# max32570 register map
Vendor: Maxim-Integrated; Series: ARMCM4; File version: 1.0
CPU: CM4 r2p1, little endian, MPU, FPU, 3 interrupt priority bits
Registers are 32-bit, read-write, reset 0x0 unless marked. A register's access mark holds for its fields unless they carry their own. Offsets are from the block's base; [hi:lo] are bit positions; {n}, {i} and the like mark numbered series; 'fields as' and 'values as' point back to an identical list.

## TRIMSIR — Trim System Initilazation Registers
Base 0x40005400
0x00 rsv0 — RFU
0x08 BB_SIR2 ro — System Init. Configuration Register 2.
0x0C BB_SIR3 ro — System Init. Configuration Register 3.

## MCR — Misc Control.
Base 0x40006C00
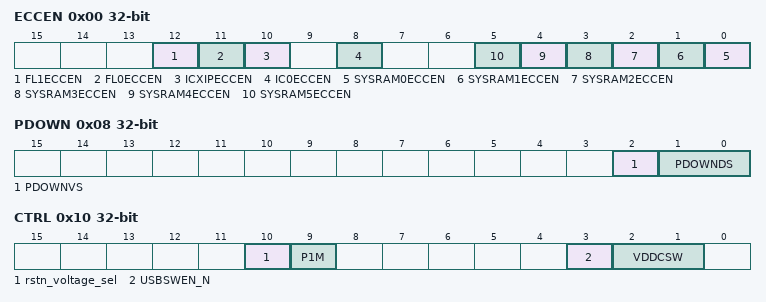
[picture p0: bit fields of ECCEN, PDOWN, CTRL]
0x00 ECCEN — ECC Enable Register
  [all] fields
    0=dis (disabled.); 1=en (enabled.)
  [12] FL1ECCEN — Flash1 ECC Enable.
  [11] FL0ECCEN — Flash0 ECC Enable.
  [10] ICXIPECCEN — IcacheXIP ECC Enable.
  [8] IC0ECCEN — Icache0 ECC Enable.
  [n] SYSRAM{n}ECCEN (n=0..5) — ECC System RAM Enable.
0x08 PDOWN — PDOWN Drive Strength
  [2] PDOWNVS — PDOWN Voltage Select
  [1:0] PDOWNDS — PDOWN Drive Strength
0x10 CTRL — Misc Power State Control Register
  [10] rstn_voltage_sel — Error! Description not Found!
  [9] P1M — Enable the Reset Pad Pull Up Resistors
    0=1m (1MOhm Pullup); 1=25k (25kOhm Pullup.)
  [3] USBSWEN_N — USB Switch Control
    1=off (USB SW off in LP modes); 0=on (USB SW On)
  [2:1] VDDCSW — Controls switching of VCORE

## CAMERAIF — Parallel Camera Interface.
Base 0x4000E000
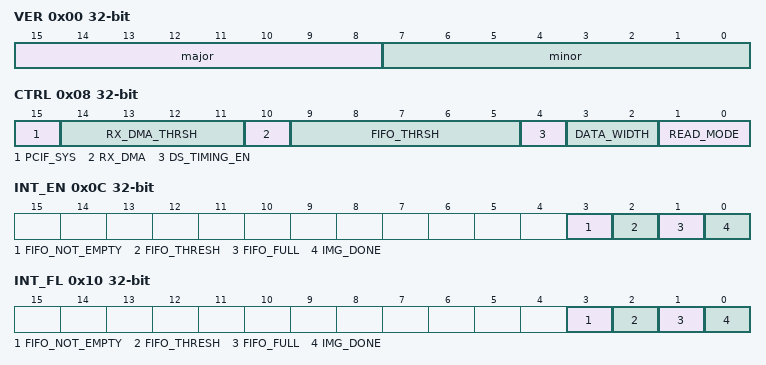
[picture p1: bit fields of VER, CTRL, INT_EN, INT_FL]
0x00 VER — Hardware Version.
  [15:8] major — Major Version Number.
  [7:0] minor — Minor Version Number.
0x04 FIFO_SIZE — FIFO Depth.
  [7:0] fifo_size
0x08 CTRL — Control Register.
  [15] PCIF_SYS — PCIF Control.
    0=dis (PCIF disabled.); 1=en (PCIF enabled.)
  [14:11] RX_DMA_THRSH — DMA Threshold.
  [10] RX_DMA — DMA Enable.
    0=dis (DMA disabled.); 1=en (DMA enabled.)
  [9:5] FIFO_THRSH — Data FIFO Threshold.
  [4] DS_TIMING_EN — DS Timing Enable.
    0=dis (Timing from VSYNC and HSYNC.); 1=en (Timing embedded in data using SAV and EAV codes.)
  [3:2] DATA_WIDTH
    0=8bit; 1=10bit; 2=12bit
  [1:0] READ_MODE
    0=dis (Camera Interface Disabled.); 1=single_img (Single Image Capture.); 2=Continuous Image Capture
0x0C INT_EN — Interrupt Enable Register.
  [3] FIFO_NOT_EMPTY
  [2] FIFO_THRESH — FIFO Threshold Level Met.
  [1] FIFO_FULL
  [0] IMG_DONE — Image Done.
0x10 INT_FL — Interrupt Flag Register.
  fields as INT_EN
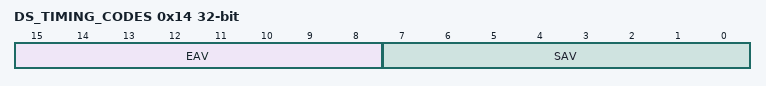
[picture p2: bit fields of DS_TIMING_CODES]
0x14 DS_TIMING_CODES — DS Timing Code Register.
  [15:8] EAV — End Active Video Code.
  [7:0] SAV — Start Active Video Code.
0x30 FIFO_DATA
  [31:0] DATA — Data from FIFO to be read by DMA.

## SRCC — SPIX Cache Controller Registers.
Base 0x40033000
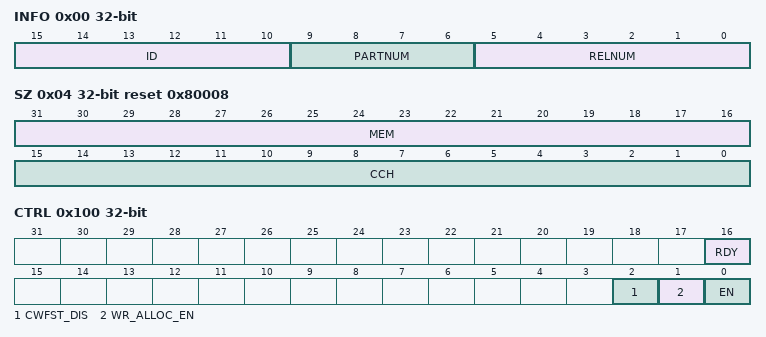
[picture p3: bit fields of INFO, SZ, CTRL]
0x00 INFO ro — Cache ID Register.
  [15:10] ID — Cache ID. This field reflects the value of the C_ID_CACHEID configuration parameter.
  [9:6] PARTNUM — Part Number. This field reflects the value of C_ID_PART_NUMBER configuration parameter.
  [5:0] RELNUM — Release Number. Identifies the RTL release version.
0x04 SZ ro reset 0x80008 — Memory Configuration Register.
  [31:16] MEM — Main Memory Size. Indicates the total size, in units of 128 Kbytes, of code memory accessible to the cache controller.
  [15:0] CCH — Cache Size. Indicates total size in Kbytes of cache.
0x100 CTRL — Cache Control and Status Register.
  [16] RDY — Cache Ready flag. Cleared by hardware when at any time the cache as a whole is invalidated (including a system reset). When this bit is 0, the cache is effectively in bypass mode (instruction fetches will come from main memory or from the line fill buffer). Set by hardware when the invalidate operation is complete and the cache is ready.
    0=notReady; 1=ready
  [2] CWFST_DIS — Critical word first and streaming disable. This bit only writeable while the cache is disabled.
    1=dis (Critical word first and streaming disabled.); 0=en (Critical word first and streaming enabled.)
  [1] WR_ALLOC_EN — Write Allocate Enable. This bit only writable while the cache is disabled.
    0=dis (Write-no-allocate.); 1=en (Write-allocate enabled.)
  [0] EN — Cache Enable. Controls whether the cache is bypassed or is in use. Changing the state of this bit will cause the instruction cache to be flushed and its contents invalidated.
    0=dis (Cache Bypassed. Instruction data is stored in the line fill buffer but is not written to main cache memory array.); 1=en (Cache Enabled.)
0x700 INVALIDATE — Invalidate All Cache Contents. Any time this register location is written (regardless of the data value), the cache controller immediately begins invalidating the entire contents of the cache memory. The cache will be in bypass mode until the invalidate operation is complete. System software can examine the Cache Ready bit (CACHE_CTRL.CACHE_RDY) to determine when the invalidate operation is complete. Note that it is not necessary to disable the cache controller prior to beginning this operation. Reads from this register always return 0.
  [31:0] INVALID — Invalidate all cache contents.
